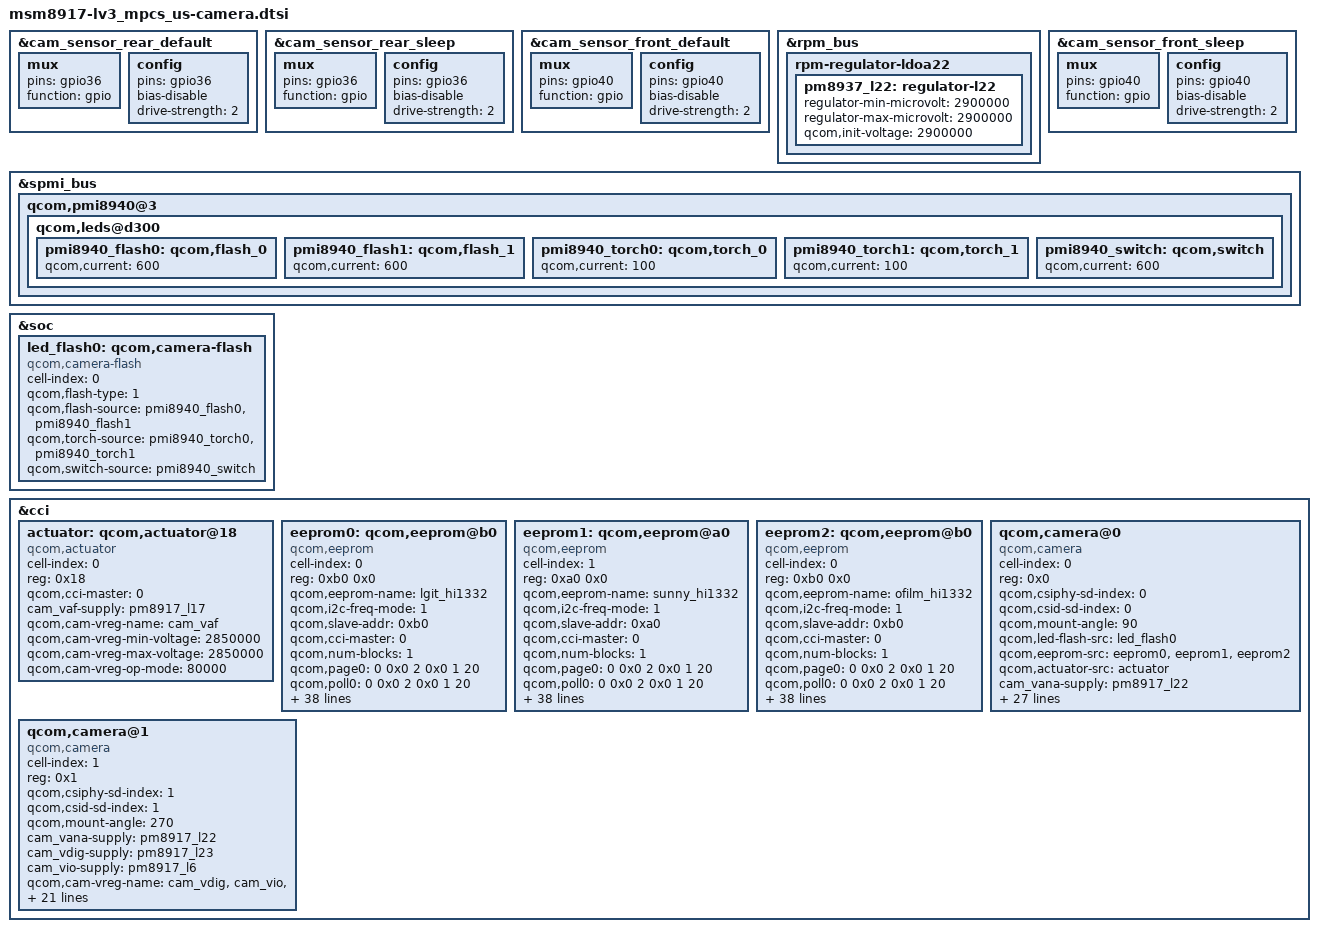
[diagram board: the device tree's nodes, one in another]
/*
 * Copyright (c) 2016, The Linux Foundation. All rights reserved.
 *
 * This program is free software; you can redistribute it and/or modify
 * it under the terms of the GNU General Public License version 2 and
 * only version 2 as published by the Free Software Foundation.
 *
 * This program is distributed in the hope that it will be useful,
 * but WITHOUT ANY WARRANTY; without even the implied warranty of
 * MERCHANTABILITY or FITNESS FOR A PARTICULAR PURPOSE.  See the
 * GNU General Public License for more details.
 */

&cam_sensor_rear_default {
	/* RESET */
	mux {
		pins = "gpio36";
		function = "gpio";
	};

	config {
		pins = "gpio36";
		bias-disable; /* No PULL */
		drive-strength = <2>; /* 2 MA */
	};
};

&cam_sensor_rear_sleep {
	/* RESET */
	mux {
		pins = "gpio36";
		function = "gpio";
	};

	config {
		pins = "gpio36";
		bias-disable; /* No PULL */
		drive-strength = <2>; /* 2 MA */
	};
};

&cam_sensor_front_default {
	/* RESET */
	mux {
		pins = "gpio40";
		function = "gpio";
	};

	config {
		pins = "gpio40";
		bias-disable; /* No PULL */
		drive-strength = <2>; /* 2 MA */
	};
};

&rpm_bus {
	rpm-regulator-ldoa22 {
		status = "okay";
		pm8937_l22: regulator-l22 {
			regulator-min-microvolt = <2900000>;
			regulator-max-microvolt = <2900000>;
			qcom,init-voltage = <2900000>;
			status = "okay";
		};
	};
};

&cam_sensor_front_sleep {
	/* RESET */
	mux {
		pins = "gpio40";
		function = "gpio";
	};

	config {
		pins = "gpio40";
		bias-disable; /* No PULL */
		drive-strength = <2>; /* 2 MA */
	};
};

&spmi_bus {
qcom,pmi8940@3 {
	qcom,leds@d300 {
			pmi8940_flash0: qcom,flash_0 {
				qcom,current = <600>;
			};
			pmi8940_flash1: qcom,flash_1 {
				qcom,current = <600>;
			};
			pmi8940_torch0: qcom,torch_0 {
				qcom,current = <100>;
			};
			pmi8940_torch1: qcom,torch_1 {
				qcom,current = <100>;
			};
			pmi8940_switch: qcom,switch {
				qcom,current = <600>;
			};
	};
};
};

&soc {
	led_flash0: qcom,camera-flash {
		cell-index = <0>;
		compatible = "qcom,camera-flash";
		qcom,flash-type = <1>;
		qcom,flash-source = <&pmi8940_flash0 &pmi8940_flash1>;
		qcom,torch-source = <&pmi8940_torch0 &pmi8940_torch1>;
		qcom,switch-source = <&pmi8940_switch>;
	};
};

&cci {

	actuator: qcom,actuator@18 {
		cell-index = <0>;
		reg = <0x18>;
		compatible = "qcom,actuator";
		qcom,cci-master = <0>;
		cam_vaf-supply = <&pm8917_l17>;
		qcom,cam-vreg-name = "cam_vaf";
		qcom,cam-vreg-min-voltage = <2850000>;
		qcom,cam-vreg-max-voltage = <2850000>;
		qcom,cam-vreg-op-mode = <80000>;
	};

	eeprom0: qcom,eeprom@b0 {
		cell-index = <0>;
		reg = <0xb0 0x0>;
		qcom,eeprom-name = "lgit_hi1332";
		compatible = "qcom,eeprom";
		qcom,i2c-freq-mode = <1>; //fast-mode
		qcom,slave-addr = <0xb0>;
		qcom,cci-master = <0>;

		qcom,num-blocks = <1>;
		qcom,page0 = <0 0x0 2 0x0 1 20>; // valid size, addr, addr_t, data, data_t, delay
		qcom,poll0 = <0 0x0 2 0x0 1 20>;
		qcom,mem0  = <0x800 0x0 2 0 1 0>; // EEPROM READ

		qcom,cmm-data-support;
		qcom,cmm-data-compressed;
		qcom,cmm-data-offset = <0>;
		qcom,cmm-data-size = <0>;

		cam_vana-supply = <&pm8917_l22>;
		cam_vdig-supply = <&pm8917_l23>;
		cam_vio-supply  = <&pm8917_l6>;
		cam_vaf-supply  = <&pm8917_l17>;
		qcom,cam-vreg-name = "cam_vdig", "cam_vio", "cam_vana", "cam_vaf";
		qcom,cam-vreg-min-voltage = <1200000 0 2900000 2850000>;
		qcom,cam-vreg-max-voltage = <1200000 0 2900000 2850000>;
		qcom,cam-vreg-op-mode = <200000 0 80000 100000>;
		qcom,gpio-no-mux = <0>;
		pinctrl-names = "cam_default", "cam_suspend";
		pinctrl-0 = <&cam_sensor_mclk0_default &cam_sensor_rear_default>;
		pinctrl-1 = <&cam_sensor_mclk0_sleep &cam_sensor_rear_sleep>;
		gpios = <&tlmm 26 0>, //clk
			<&tlmm 36 0>;  //reset
		qcom,gpio-reset = <1>;
		qcom,gpio-req-tbl-num = <0 1>;
		qcom,gpio-req-tbl-flags = <1 0>;
		qcom,gpio-req-tbl-label = "CAMIF_MCLK0", "CAM_RESET0";

		qcom,cam-power-seq-type = "sensor_vreg", "sensor_vreg", "sensor_vreg",
			"sensor_clk", "sensor_gpio";
		qcom,cam-power-seq-val = "cam_vana", "cam_vdig", "cam_vio",
			"sensor_cam_mclk", "sensor_gpio_reset";
		qcom,cam-power-seq-cfg-val = <1 1 1 24000000 1>;
		qcom,cam-power-seq-delay = <1 1 1 5 5>;

		status = "ok";
		clocks = <&clock_gcc clk_mclk0_clk_src>,
			<&clock_gcc clk_gcc_camss_mclk0_clk>;
		clock-names = "cam_src_clk", "cam_clk";
		qcom,clock-rates = <24000000 0>;
		qcom,sensor-position = <0>;
	};	

	eeprom1: qcom,eeprom@a0 {
		cell-index = <1>;
		reg = <0xa0 0x0>;
		qcom,eeprom-name = "sunny_hi1332";
		compatible = "qcom,eeprom";
		qcom,i2c-freq-mode = <1>; //fast-mode
		qcom,slave-addr = <0xa0>;
		qcom,cci-master = <0>;

		qcom,num-blocks = <1>;
		qcom,page0 = <0 0x0 2 0x0 1 20>; // valid size, addr, addr_t, data, data_t, delay
		qcom,poll0 = <0 0x0 2 0x0 1 20>;
		qcom,mem0  = <0x800 0x0 2 0 1 0>; // EEPROM READ

		qcom,cmm-data-support;
		qcom,cmm-data-compressed;
		qcom,cmm-data-offset = <0>;
		qcom,cmm-data-size = <0>;

		cam_vana-supply = <&pm8917_l22>;
		cam_vdig-supply = <&pm8917_l23>;
		cam_vio-supply  = <&pm8917_l6>;
		cam_vaf-supply  = <&pm8917_l17>;
		qcom,cam-vreg-name = "cam_vdig", "cam_vio", "cam_vana", "cam_vaf";
		qcom,cam-vreg-min-voltage = <1200000 0 2900000 2850000>;
		qcom,cam-vreg-max-voltage = <1200000 0 2900000 2850000>;
		qcom,cam-vreg-op-mode = <200000 0 80000 100000>;
		qcom,gpio-no-mux = <0>;
		pinctrl-names = "cam_default", "cam_suspend";
		pinctrl-0 = <&cam_sensor_mclk0_default &cam_sensor_rear_default>;
		pinctrl-1 = <&cam_sensor_mclk0_sleep &cam_sensor_rear_sleep>;
		gpios = <&tlmm 26 0>, //clk
			<&tlmm 36 0>;  //reset
		qcom,gpio-reset = <1>;
		qcom,gpio-req-tbl-num = <0 1>;
		qcom,gpio-req-tbl-flags = <1 0>;
		qcom,gpio-req-tbl-label = "CAMIF_MCLK0", "CAM_RESET0";

		qcom,cam-power-seq-type = "sensor_vreg", "sensor_vreg", "sensor_vreg",
			"sensor_clk", "sensor_gpio";
		qcom,cam-power-seq-val = "cam_vana", "cam_vdig", "cam_vio",
			"sensor_cam_mclk", "sensor_gpio_reset";
		qcom,cam-power-seq-cfg-val = <1 1 1 24000000 1>;
		qcom,cam-power-seq-delay = <1 1 1 5 5>;

		status = "ok";
		clocks = <&clock_gcc clk_mclk0_clk_src>,
			<&clock_gcc clk_gcc_camss_mclk0_clk>;
		clock-names = "cam_src_clk", "cam_clk";
		qcom,clock-rates = <24000000 0>;
		qcom,sensor-position = <0>;
	};

	eeprom2: qcom,eeprom@b0 {
		cell-index = <0>;
		reg = <0xb0 0x0>;
		qcom,eeprom-name = "ofilm_hi1332";
		compatible = "qcom,eeprom";
		qcom,i2c-freq-mode = <1>; //fast-mode
		qcom,slave-addr = <0xb0>;
		qcom,cci-master = <0>;

		qcom,num-blocks = <1>;
		qcom,page0 = <0 0x0 2 0x0 1 20>; // valid size, addr, addr_t, data, data_t, delay
		qcom,poll0 = <0 0x0 2 0x0 1 20>;
		qcom,mem0  = <0x800 0x0 2 0 1 0>; // EEPROM READ

		qcom,cmm-data-support;
		qcom,cmm-data-compressed;
		qcom,cmm-data-offset = <0>;
		qcom,cmm-data-size = <0>;

		cam_vana-supply = <&pm8917_l22>;
		cam_vdig-supply = <&pm8917_l23>;
		cam_vio-supply  = <&pm8917_l6>;
		cam_vaf-supply  = <&pm8917_l17>;
		qcom,cam-vreg-name = "cam_vdig", "cam_vio", "cam_vana", "cam_vaf";
		qcom,cam-vreg-min-voltage = <1200000 0 2900000 2850000>;
		qcom,cam-vreg-max-voltage = <1200000 0 2900000 2850000>;
		qcom,cam-vreg-op-mode = <200000 0 80000 100000>;
		qcom,gpio-no-mux = <0>;
		pinctrl-names = "cam_default", "cam_suspend";
		pinctrl-0 = <&cam_sensor_mclk0_default &cam_sensor_rear_default>;
		pinctrl-1 = <&cam_sensor_mclk0_sleep &cam_sensor_rear_sleep>;
		gpios = <&tlmm 26 0>, //clk
			<&tlmm 36 0>;  //reset
		qcom,gpio-reset = <1>;
		qcom,gpio-req-tbl-num = <0 1>;
		qcom,gpio-req-tbl-flags = <1 0>;
		qcom,gpio-req-tbl-label = "CAMIF_MCLK0", "CAM_RESET0";

		qcom,cam-power-seq-type = "sensor_vreg", "sensor_vreg", "sensor_vreg",
			"sensor_clk", "sensor_gpio";
		qcom,cam-power-seq-val = "cam_vana", "cam_vdig", "cam_vio",
			"sensor_cam_mclk", "sensor_gpio_reset";
		qcom,cam-power-seq-cfg-val = <1 1 1 24000000 1>;
		qcom,cam-power-seq-delay = <1 1 1 5 5>;

		status = "ok";
		clocks = <&clock_gcc clk_mclk0_clk_src>,
			<&clock_gcc clk_gcc_camss_mclk0_clk>;
		clock-names = "cam_src_clk", "cam_clk";
		qcom,clock-rates = <24000000 0>;
		qcom,sensor-position = <0>;
	};


	qcom,camera@0 {
		cell-index = <0>;
		compatible = "qcom,camera";
		reg = <0x0>;
		qcom,csiphy-sd-index = <0>;
		qcom,csid-sd-index = <0>;
		qcom,mount-angle = <90>;
		qcom,led-flash-src = <&led_flash0>;
		qcom,eeprom-src = <&eeprom0 &eeprom1 &eeprom2>;
		qcom,actuator-src = <&actuator>;

		cam_vana-supply = <&pm8917_l22>;
		cam_vdig-supply = <&pm8917_l23>;
		cam_vio-supply  = <&pm8917_l6>;
		cam_vaf-supply  = <&pm8917_l17>;
		qcom,cam-vreg-name = "cam_vdig", "cam_vio", "cam_vana", "cam_vaf";
		qcom,cam-vreg-min-voltage = <1200000 0 2900000 2850000>;
		qcom,cam-vreg-max-voltage = <1200000 0 2900000 2850000>;
		qcom,cam-vreg-op-mode = <200000 0 80000 100000>;
		qcom,gpio-no-mux = <0>;
		pinctrl-names = "cam_default", "cam_suspend";
		pinctrl-0 = <&cam_sensor_mclk0_default &cam_sensor_rear_default>;
		pinctrl-1 = <&cam_sensor_mclk0_sleep &cam_sensor_rear_sleep>;
		gpios = <&tlmm 26 0>, //clk
			<&tlmm 36 0>;  //reset
		qcom,gpio-reset = <1>;
		qcom,gpio-req-tbl-num = <0 1>;
		qcom,gpio-req-tbl-flags = <1 0>;
		qcom,gpio-req-tbl-label = "CAMIF_MCLK0",
			"CAM_RESET0";

		qcom,sensor-position = <0>;
		qcom,sensor-mode = <0>;
		qcom,cci-master = <0>;
		status = "ok";
		clocks = <&clock_gcc clk_mclk0_clk_src>,
				<&clock_gcc clk_gcc_camss_mclk0_clk>;
		clock-names = "cam_src_clk", "cam_clk";
		qcom,clock-rates = <24000000 0>;
	};

	qcom,camera@1 {
		cell-index = <1>;
		compatible = "qcom,camera";
		reg = <0x1>;
		qcom,csiphy-sd-index = <1>;
		qcom,csid-sd-index = <1>;
		qcom,mount-angle = <270>;

		cam_vana-supply = <&pm8917_l22>;
		cam_vdig-supply = <&pm8917_l23>;
		cam_vio-supply  = <&pm8917_l6>;
		qcom,cam-vreg-name = "cam_vdig", "cam_vio", "cam_vana";
		qcom,cam-vreg-min-voltage = <1200000 0 2900000>;
		qcom,cam-vreg-max-voltage = <1200000 0 2900000>;
		qcom,cam-vreg-op-mode = <200000 0 80000>;
		qcom,gpio-no-mux = <0>;
		pinctrl-names = "cam_default", "cam_suspend";
		pinctrl-0 = <&cam_sensor_mclk2_default &cam_sensor_front_default>;
		pinctrl-1 = <&cam_sensor_mclk2_sleep &cam_sensor_front_sleep>;
		gpios = <&tlmm 28 0>, //clk
			<&tlmm 40 0>;  //reset
		qcom,gpio-reset = <1>;
		qcom,gpio-req-tbl-num = <0 1>;
		qcom,gpio-req-tbl-flags = <1 0>;
		qcom,gpio-req-tbl-label = "CAMIF_MCLK2",
			"CAM_RESET1";

		qcom,sensor-position = <1>;
		qcom,sensor-mode = <0>;
		qcom,cci-master = <1>;
		status = "ok";
		clocks = <&clock_gcc clk_mclk2_clk_src>,
				<&clock_gcc clk_gcc_camss_mclk2_clk>;
		clock-names = "cam_src_clk", "cam_clk";
		qcom,clock-rates = <24000000 0>;
	};
};
